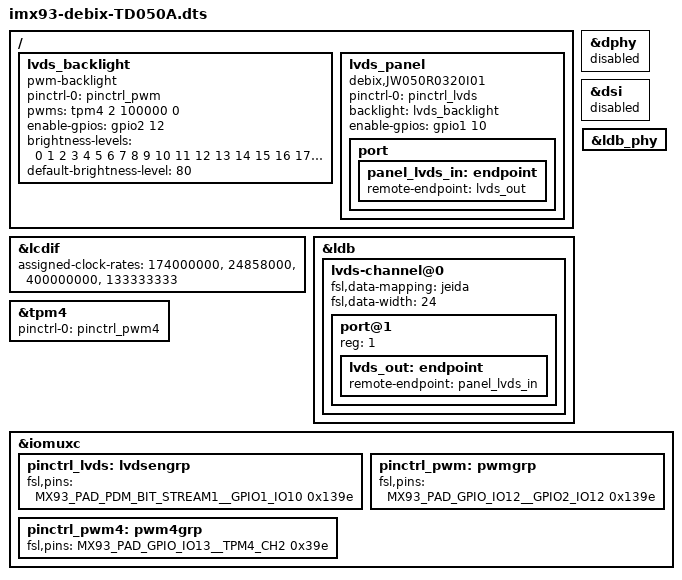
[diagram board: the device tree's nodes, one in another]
// SPDX-License-Identifier: (GPL-2.0+ OR MIT)
/*
 * Copyright 2022 NXP
 */

#include "imx93-11x11-evk.dts"

/ {

	lvds_backlight: lvds_backlight {
		compatible = "pwm-backlight";
		pinctrl-names = "default";
		pinctrl-0 = <&pinctrl_pwm>;
		pwms = <&tpm4 2 100000 0>;
		enable-gpios = <&gpio2 12 GPIO_ACTIVE_HIGH>;
		//power-supply = <&reg_vdd_12v>;
		status = "okay";

		brightness-levels = < 0  1  2  3  4  5  6  7  8  9
				     10 11 12 13 14 15 16 17 18 19
				     20 21 22 23 24 25 26 27 28 29
				     30 31 32 33 34 35 36 37 38 39
				     40 41 42 43 44 45 46 47 48 49
				     50 51 52 53 54 55 56 57 58 59
				     60 61 62 63 64 65 66 67 68 69
				     70 71 72 73 74 75 76 77 78 79
				     80 81 82 83 84 85 86 87 88 89
				     90 91 92 93 94 95 96 97 98 99
				    100>;
		default-brightness-level = <80>;
	};

	lvds_panel {
		pinctrl-names = "default";
		pinctrl-0 = <&pinctrl_lvds>;
		compatible = "debix,JW050R0320I01";
                backlight = <&lvds_backlight>;
		enable-gpios = <&gpio1 10 GPIO_ACTIVE_HIGH>;

		port {
			panel_lvds_in: endpoint {
				remote-endpoint = <&lvds_out>;
			};
		};
	};

	//debix-pwm {
	//	compatible = "debix,debix-pwm";    /* compatible属性 */
	//	power-gpios = <&gpio2 12 0>;           /* pwm en gpio */
	//	pwm-gpios = <&gpio2 13 0>;           /* pwm输出gpio */
	//	npwm = <1>;                     /* pwm通道个数 */
	//	status = "disabled";
	//};
};

/*
&adv7535 {
	status = "disabled";
};
*/

&dphy {
	status = "disabled";
};

&dsi {
	status = "disabled";
};

&lcdif {
	assigned-clock-rates = <174000000>, <24858000>, <400000000>, <133333333>;
};

&ldb {
	status = "okay";

	lvds-channel@0 {
		fsl,data-mapping = "jeida";
		//fsl,data-mapping = "spwg";
		fsl,data-width = <24>;
		status = "okay";

		port@1 {
			reg = <1>;

			lvds_out: endpoint {
				remote-endpoint = <&panel_lvds_in>;
			};
		};
	};
};

&ldb_phy {
	status = "okay";
};

&tpm4 {
	pinctrl-names = "default";
	pinctrl-0 = <&pinctrl_pwm4>;
	status = "okay";
};


&iomuxc {
        pinctrl_lvds: lvdsengrp {
                fsl,pins = <
			MX93_PAD_PDM_BIT_STREAM1__GPIO1_IO10 0x139e
                >;
        };
        pinctrl_pwm: pwmgrp {
                fsl,pins = <
			MX93_PAD_GPIO_IO12__GPIO2_IO12	0x139e
			//MX93_PAD_GPIO_IO13__GPIO2_IO13	0x139e
                >;
        };
	pinctrl_pwm4: pwm4grp {
		fsl,pins = <
			MX93_PAD_GPIO_IO13__TPM4_CH2 0x39e
		>;
	};

};
